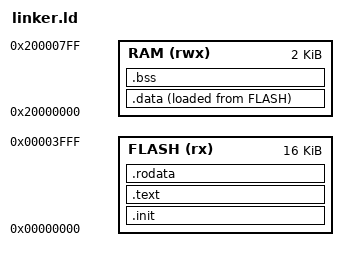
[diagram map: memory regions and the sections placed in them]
ENTRY(_start)

MEMORY
{
    FLASH (rx)  : ORIGIN = 0x00000000, LENGTH = 16K
    RAM   (rwx) : ORIGIN = 0x20000000, LENGTH = 2K
}

SECTIONS
{
    .init : {
        *(.init)
    } > FLASH

    .text : {
        *(.text*)
    } > FLASH

    .rodata : {
        *(.rodata*)
    } > FLASH

    .data : {
        _data_start = .;
        *(.data*)
        _data_end = .;
    } > RAM AT > FLASH

    .bss : {
        _bss_start = .;
        *(.bss*)
        *(COMMON)
        _bss_end = .;
    } > RAM

    _stack_top = ORIGIN(RAM) + LENGTH(RAM);
}
